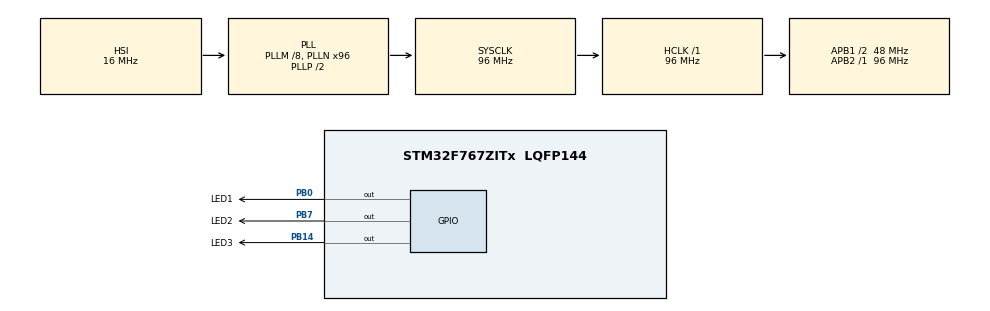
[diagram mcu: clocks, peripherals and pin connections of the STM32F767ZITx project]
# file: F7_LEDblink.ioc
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Mcu.Family=STM32F7
Mcu.Name=STM32F767ZITx
Mcu.Package=LQFP144
NVIC.PriorityGroup=NVIC_PRIORITYGROUP_4
NVIC.RCC_IRQn=true\:0\:0\:false\:false\:true\:true\:false
PA13.Mode=Serial_Wire
PA13.Signal=SYS_JTMS-SWDIO
PA14.Mode=Serial_Wire
PA14.Signal=SYS_JTCK-SWCLK
PB0.GPIO_Label=LED1
PB0.Signal=GPIO_Output
PB14.GPIO_Label=LED3
PB14.Signal=GPIO_Output
PB7.GPIO_Label=LED2
PB7.Signal=GPIO_Output
ProjectManager.HeapSize=0x200
ProjectManager.StackSize=0x400
ProjectManager.TargetToolchain=TrueSTUDIO
RCC.48MHZClocksFreq_Value=24000000
RCC.AHBFreq_Value=96000000
RCC.APB1CLKDivider=RCC_HCLK_DIV2
RCC.APB1Freq_Value=48000000
RCC.APB1TimFreq_Value=96000000
RCC.APB2Freq_Value=96000000
RCC.APB2TimFreq_Value=96000000
RCC.CortexFreq_Value=96000000
RCC.HCLKFreq_Value=96000000
RCC.HSE_VALUE=8000000
RCC.HSI_VALUE=16000000
RCC.PLLM=8
RCC.PLLMUL=RCC_PLL_MUL9
RCC.PLLN=96
RCC.PLLQ=4
RCC.PRESCALERUSB=RCC_USBCLKSOURCE_PLL_DIV1_5
RCC.SYSCLKFreq_VALUE=96000000
RCC.SYSCLKSource=RCC_SYSCLKSOURCE_PLLCLK
RCC.SYSCLKSourceVirtual=RCC_SYSCLKSOURCE_PLLCLK
RCC.USBFreq_Value=48000000
RCC.VCOOutputFreq_Value=192000000
board=NUCLEO-F767ZI

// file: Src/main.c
/* USER CODE BEGIN Header */
/**
  ******************************************************************************
  * @file           : main.c
  * @brief          : Main program body
  ******************************************************************************
  * @attention
  *
  * <h2><center>&copy; Copyright (c) 2019 STMicroelectronics.
  * All rights reserved.</center></h2>
  *
  * This software component is licensed by ST under BSD 3-Clause license,
  * the "License"; You may not use this file except in compliance with the
  * License. You may obtain a copy of the License at:
  *                        opensource.org/licenses/BSD-3-Clause
  *
  ******************************************************************************
  */
/* USER CODE END Header */

#include "main.h"

void SystemClock_Config(void);
static void MX_GPIO_Init(void);

int main(void)
{

  /* MCU Configuration--------------------------------------------------------*/

  /* Reset of all peripherals, Initializes the Flash interface and the Systick. */
  HAL_Init();

  /* Configure the system clock */
  SystemClock_Config();

  /* Initialize all configured peripherals */
  MX_GPIO_Init();

  /* Infinite loop */
  while (1)
  {

    /* USER CODE BEGIN 3 */
	  //HAL_GPIO_TogglePin(GPIOB,GPIO_PIN_0);
	  HAL_GPIO_TogglePin(LED1_GPIO_Port,LED1_Pin);//alternative
	  HAL_Delay(100);
	 // HAL_GPIO_TogglePin(GPIOB,GPIO_PIN_7);
	  HAL_GPIO_TogglePin(LED2_GPIO_Port,LED2_Pin);//alternative
	  HAL_Delay(100);
	  //HAL_GPIO_TogglePin(GPIOB,GPIO_PIN_14);
	  HAL_GPIO_TogglePin(LED3_GPIO_Port,LED3_Pin);//alternative
	  HAL_Delay(100);
  }
  /* USER CODE END 3 */
}

void SystemClock_Config(void)
{
  RCC_OscInitTypeDef RCC_OscInitStruct = {0};
  RCC_ClkInitTypeDef RCC_ClkInitStruct = {0};

  /** Configure the main internal regulator output voltage
  */
  __HAL_RCC_PWR_CLK_ENABLE();
  __HAL_PWR_VOLTAGESCALING_CONFIG(PWR_REGULATOR_VOLTAGE_SCALE3);
  /** Initializes the CPU, AHB and APB busses clocks
  */
  RCC_OscInitStruct.OscillatorType = RCC_OSCILLATORTYPE_HSI;
  RCC_OscInitStruct.HSIState = RCC_HSI_ON;
  RCC_OscInitStruct.HSICalibrationValue = RCC_HSICALIBRATION_DEFAULT;
  RCC_OscInitStruct.PLL.PLLState = RCC_PLL_ON;
  RCC_OscInitStruct.PLL.PLLSource = RCC_PLLSOURCE_HSI;
  RCC_OscInitStruct.PLL.PLLM = 8;
  RCC_OscInitStruct.PLL.PLLN = 96;
  RCC_OscInitStruct.PLL.PLLP = RCC_PLLP_DIV2;
  RCC_OscInitStruct.PLL.PLLQ = 4;
  if (HAL_RCC_OscConfig(&RCC_OscInitStruct) != HAL_OK)
  {
    Error_Handler();
  }
  /** Activate the Over-Drive mode
  */
  if (HAL_PWREx_EnableOverDrive() != HAL_OK)
  {
    Error_Handler();
  }
  /** Initializes the CPU, AHB and APB busses clocks
  */
  RCC_ClkInitStruct.ClockType = RCC_CLOCKTYPE_HCLK|RCC_CLOCKTYPE_SYSCLK
                              |RCC_CLOCKTYPE_PCLK1|RCC_CLOCKTYPE_PCLK2;
  RCC_ClkInitStruct.SYSCLKSource = RCC_SYSCLKSOURCE_PLLCLK;
  RCC_ClkInitStruct.AHBCLKDivider = RCC_SYSCLK_DIV1;
  RCC_ClkInitStruct.APB1CLKDivider = RCC_HCLK_DIV2;
  RCC_ClkInitStruct.APB2CLKDivider = RCC_HCLK_DIV1;

  if (HAL_RCC_ClockConfig(&RCC_ClkInitStruct, FLASH_LATENCY_3) != HAL_OK)
  {
    Error_Handler();
  }
}

static void MX_GPIO_Init(void)
{
  GPIO_InitTypeDef GPIO_InitStruct = {0};

  /* GPIO Ports Clock Enable */
  __HAL_RCC_GPIOB_CLK_ENABLE();
  __HAL_RCC_GPIOA_CLK_ENABLE();

  /*Configure GPIO pin Output Level */
  HAL_GPIO_WritePin(GPIOB, LED1_Pin|LED3_Pin|LED2_Pin, GPIO_PIN_RESET);

  /*Configure GPIO pins : LED1_Pin LED3_Pin LED2_Pin */
  GPIO_InitStruct.Pin = LED1_Pin|LED3_Pin|LED2_Pin;
  GPIO_InitStruct.Mode = GPIO_MODE_OUTPUT_PP;
  GPIO_InitStruct.Pull = GPIO_NOPULL;
  GPIO_InitStruct.Speed = GPIO_SPEED_FREQ_LOW;
  HAL_GPIO_Init(GPIOB, &GPIO_InitStruct);

}

void Error_Handler(void)
{
}

/************************ (C) COPYRIGHT STMicroelectronics *****END OF FILE****/
